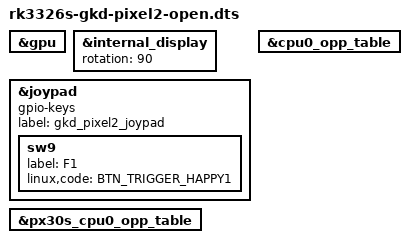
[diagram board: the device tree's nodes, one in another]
// SPDX-License-Identifier: (GPL-2.0-or-later OR MIT)
/*
 * Android and Panfrost adaptations of the repository's licensed AURKNIX
 * Pixel 2 board tree. The boot bundle includes no stock device tree.
 */

#include "rk3326s-gkd-pixel2.dts"

&gpu {
	/* Panfrost looks up lowercase interrupt names. Keep the IRQ order. */
	interrupt-names = "gpu", "mmu", "job";
};

&internal_display {
	/* Match the orientation of the known Android panel configuration. */
	rotation = <90>;
};

&joypad {
	compatible = "gpio-keys";
	label = "gkd_pixel2_joypad";
	/delete-property/ joypad-name;
	/delete-property/ joypad-vendor;
	/delete-property/ joypad-product;
	/delete-property/ joypad-revision;
	/delete-property/ amux-count;
	/delete-property/ poll-interval;
	/delete-property/ pwms;
	/delete-property/ pwm-names;

	/* The Pixel 2 has no analog sticks or stick-click buttons. */
	/delete-node/ sw10;
	/delete-node/ sw13;

	sw9 {
		label = "F1";
		linux,code = <BTN_TRIGGER_HAPPY1>;
	};
};

/* Preserve the Android reference build's CPU frequency limit. */
&cpu0_opp_table {
	/delete-node/ opp-1512000000;
};

&px30s_cpu0_opp_table {
	/delete-node/ opp-1512000000;
};
